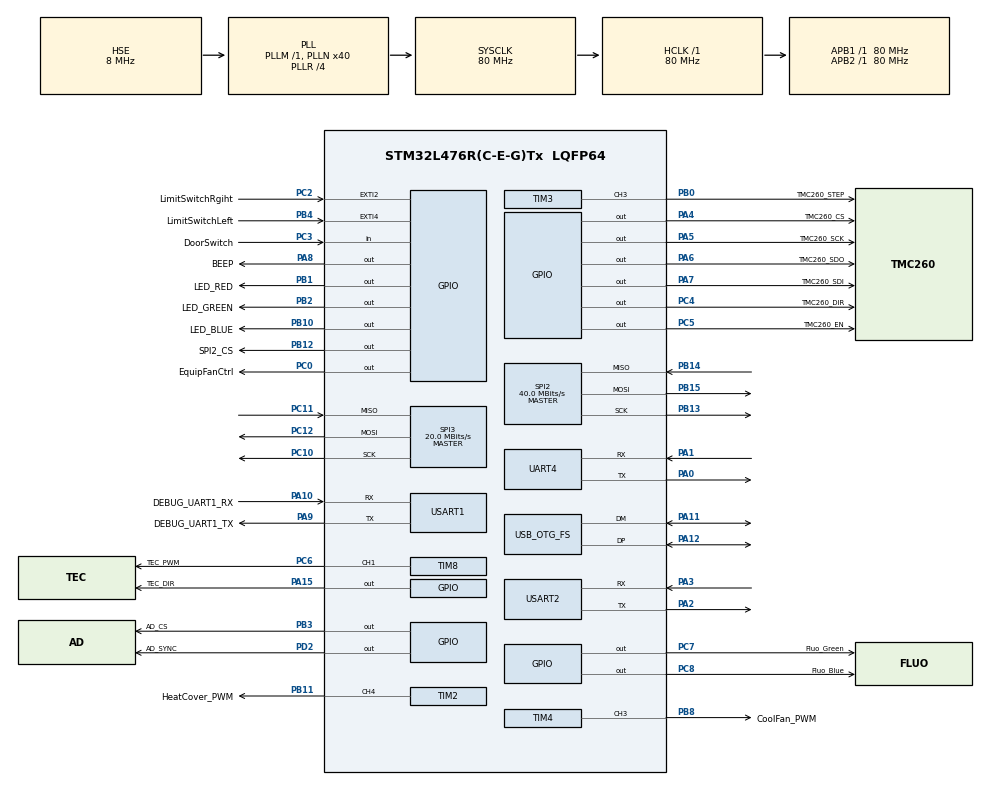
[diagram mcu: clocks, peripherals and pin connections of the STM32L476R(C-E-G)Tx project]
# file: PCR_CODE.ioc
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Dma.Request0=UART4_TX
Dma.Request1=USART2_TX
Dma.UART4_TX.0.Direction=DMA_MEMORY_TO_PERIPH
Dma.UART4_TX.0.Instance=DMA2_Channel3
Dma.UART4_TX.0.MemDataAlignment=DMA_MDATAALIGN_BYTE
Dma.UART4_TX.0.MemInc=DMA_MINC_ENABLE
Dma.UART4_TX.0.Mode=DMA_NORMAL
Dma.UART4_TX.0.PeriphDataAlignment=DMA_PDATAALIGN_BYTE
Dma.UART4_TX.0.PeriphInc=DMA_PINC_DISABLE
Dma.UART4_TX.0.Priority=DMA_PRIORITY_LOW
Dma.USART2_TX.1.Direction=DMA_MEMORY_TO_PERIPH
Dma.USART2_TX.1.Instance=DMA1_Channel7
Dma.USART2_TX.1.MemDataAlignment=DMA_MDATAALIGN_BYTE
Dma.USART2_TX.1.MemInc=DMA_MINC_ENABLE
Dma.USART2_TX.1.Mode=DMA_NORMAL
Dma.USART2_TX.1.PeriphDataAlignment=DMA_PDATAALIGN_BYTE
Dma.USART2_TX.1.PeriphInc=DMA_PINC_DISABLE
Dma.USART2_TX.1.Priority=DMA_PRIORITY_LOW
FATFS._CODE_PAGE=437
FATFS._MAX_SS=4096
FATFS._USE_LFN=3
Mcu.Family=STM32L4
Mcu.Name=STM32L476R(C-E-G)Tx
Mcu.Package=LQFP64
NVIC.DMA1_Channel7_IRQn=true\:0\:0\:false\:false\:true\:false\:true
NVIC.DMA2_Channel3_IRQn=true\:3\:0\:true\:false\:true\:false\:true
NVIC.EXTI2_IRQn=true\:4\:0\:true\:false\:true\:true\:true
NVIC.EXTI4_IRQn=true\:4\:0\:true\:false\:true\:true\:true
NVIC.OTG_FS_IRQn=true\:8\:0\:true\:false\:true\:false\:true
NVIC.PriorityGroup=NVIC_PRIORITYGROUP_4
NVIC.TIM3_IRQn=true\:2\:0\:true\:false\:true\:true\:false
NVIC.TIM6_DAC_IRQn=true\:5\:0\:true\:false\:true\:true\:false
NVIC.TIM7_IRQn=true\:1\:0\:true\:false\:true\:true\:false
NVIC.UART4_IRQn=true\:3\:0\:true\:false\:true\:true\:true
NVIC.USART2_IRQn=true\:0\:0\:false\:false\:true\:true\:true
PA0.Mode=Asynchronous
PA0.Signal=UART4_TX
PA1.Mode=Asynchronous
PA1.Signal=UART4_RX
PA10.GPIO_Label=DEBUG_UART1_RX
PA10.Mode=Asynchronous
PA10.Signal=USART1_RX
PA11.Mode=Host_Only
PA11.Signal=USB_OTG_FS_DM
PA12.Mode=Host_Only
PA12.Signal=USB_OTG_FS_DP
PA13\ (JTMS-SWDIO).Mode=Serial_Wire
PA13\ (JTMS-SWDIO).Signal=SYS_JTMS-SWDIO
PA14\ (JTCK-SWCLK).Mode=Serial_Wire
PA14\ (JTCK-SWCLK).Signal=SYS_JTCK-SWCLK
PA15\ (JTDI).GPIO_Label=TEC_DIR
PA15\ (JTDI).Signal=GPIO_Output
PA2.Mode=Asynchronous
PA2.Signal=USART2_TX
PA3.Mode=Asynchronous
PA3.Signal=USART2_RX
PA4.GPIO_Label=TMC260_CS
PA4.GPIO_PuPd=GPIO_PULLUP
PA4.PinState=GPIO_PIN_SET
PA4.Signal=GPIO_Output
PA5.GPIO_Label=TMC260_SCK
PA5.GPIO_PuPd=GPIO_PULLUP
PA5.GPIO_Speed=GPIO_SPEED_FREQ_HIGH
PA5.Signal=GPIO_Output
PA6.GPIO_Label=TMC260_SDO
PA6.GPIO_PuPd=GPIO_PULLUP
PA6.GPIO_Speed=GPIO_SPEED_FREQ_HIGH
PA6.Signal=GPIO_Output
PA7.GPIO_Label=TMC260_SDI
PA7.GPIO_PuPd=GPIO_PULLUP
PA7.GPIO_Speed=GPIO_SPEED_FREQ_HIGH
PA7.Signal=GPIO_Output
PA8.GPIO_Label=BEEP
PA8.GPIO_PuPd=GPIO_PULLUP
PA8.Signal=GPIO_Output
PA9.GPIO_Label=DEBUG_UART1_TX
PA9.Mode=Asynchronous
PA9.Signal=USART1_TX
PB0.GPIO_Label=TMC260_STEP
PB0.Signal=S_TIM3_CH3
PB1.GPIO_Label=LED_RED
PB1.GPIO_PuPd=GPIO_PULLUP
PB1.GPIO_Speed=GPIO_SPEED_FREQ_LOW
PB1.Signal=GPIO_Output
PB10.GPIO_Label=LED_BLUE
PB10.GPIO_PuPd=GPIO_PULLUP
PB10.Signal=GPIO_Output
PB11.GPIO_Label=HeatCover_PWM
PB11.Signal=S_TIM2_CH4
PB12.GPIO_Label=SPI2_CS
PB12.GPIO_PuPd=GPIO_PULLUP
PB12.GPIO_Speed=GPIO_SPEED_FREQ_LOW
PB12.Signal=GPIO_Output
PB13.Mode=Full_Duplex_Master
PB13.Signal=SPI2_SCK
PB14.Mode=Full_Duplex_Master
PB14.Signal=SPI2_MISO
PB15.Mode=Full_Duplex_Master
PB15.Signal=SPI2_MOSI
PB2.GPIO_Label=LED_GREEN
PB2.GPIO_PuPd=GPIO_PULLUP
PB2.Signal=GPIO_Output
PB3\ (JTDO-TRACESWO).GPIO_Label=AD_CS
PB3\ (JTDO-TRACESWO).GPIO_PuPd=GPIO_PULLUP
PB3\ (JTDO-TRACESWO).Signal=GPIO_Output
PB4\ (NJTRST).GPIO_Label=LimitSwitchLeft
PB4\ (NJTRST).GPIO_ModeDefaultEXTI=GPIO_MODE_IT_FALLING
PB4\ (NJTRST).Signal=GPXTI4
PB8.GPIO_Label=CoolFan_PWM
PB8.Signal=S_TIM4_CH3
PC0.GPIO_Label=EquipFanCtrl
PC0.GPIO_PuPd=GPIO_PULLUP
PC0.Signal=GPIO_Output
PC10.Mode=Full_Duplex_Master
PC10.Signal=SPI3_SCK
PC11.Mode=Full_Duplex_Master
PC11.Signal=SPI3_MISO
PC12.Mode=Full_Duplex_Master
PC12.Signal=SPI3_MOSI
PC2.GPIO_Label=LimitSwitchRgiht
PC2.GPIO_ModeDefaultEXTI=GPIO_MODE_IT_FALLING
PC2.Signal=GPXTI2
PC3.GPIO_Label=DoorSwitch
PC3.Signal=GPIO_Input
PC4.GPIO_Label=TMC260_DIR
PC4.GPIO_PuPd=GPIO_PULLUP
PC4.GPIO_Speed=GPIO_SPEED_FREQ_LOW
PC4.Signal=GPIO_Output
PC5.GPIO_Label=TMC260_EN
PC5.GPIO_PuPd=GPIO_PULLUP
PC5.GPIO_Speed=GPIO_SPEED_FREQ_LOW
PC5.PinState=GPIO_PIN_SET
PC5.Signal=GPIO_Output
PC6.GPIO_Label=TEC_PWM
PC6.Signal=S_TIM8_CH1
PC7.GPIO_Label=Fluo_Green
PC7.GPIO_PuPd=GPIO_PULLUP
PC7.GPIO_Speed=GPIO_SPEED_FREQ_MEDIUM
PC7.Signal=GPIO_Output
PC8.GPIO_Label=Fluo_Blue
PC8.GPIO_PuPd=GPIO_PULLUP
PC8.GPIO_Speed=GPIO_SPEED_FREQ_MEDIUM
PC8.Signal=GPIO_Output
PD2.GPIO_Label=AD_SYNC
PD2.PinState=GPIO_PIN_SET
PD2.Signal=GPIO_Output
PH0-OSC_IN\ (PH0).Mode=HSE-External-Oscillator
PH0-OSC_IN\ (PH0).Signal=RCC_OSC_IN
PH1-OSC_OUT\ (PH1).Mode=HSE-External-Oscillator
PH1-OSC_OUT\ (PH1).Signal=RCC_OSC_OUT
ProjectManager.HeapSize=0xC00
ProjectManager.StackSize=0x2000
ProjectManager.TargetToolchain=MDK-ARM V5
RCC.ADCFreq_Value=48000000
RCC.AHBFreq_Value=80000000
RCC.APB1Freq_Value=80000000
RCC.APB1TimFreq_Value=80000000
RCC.APB2Freq_Value=80000000
RCC.APB2TimFreq_Value=80000000
RCC.CortexFreq_Value=80000000
RCC.HCLKFreq_Value=80000000
RCC.HSE_VALUE=8000000
RCC.HSI_VALUE=16000000
RCC.LSE_VALUE=32768
RCC.MSI_VALUE=4000000
RCC.PLLN=40
RCC.PLLR=RCC_PLLR_DIV4
RCC.PLLSAI1N=12
RCC.PLLSourceVirtual=RCC_PLLSOURCE_HSE
RCC.SYSCLKFreq_VALUE=80000000
RCC.SYSCLKSource=RCC_SYSCLKSOURCE_PLLCLK
RCC.USBFreq_Value=48000000
RCC.VCOOutputFreq_Value=320000000
SH.S_TIM2_CH4.0=TIM2_CH4,PWM Generation4 CH4
SH.S_TIM3_CH3.0=TIM3_CH3,PWM Generation3 CH3
SH.S_TIM4_CH3.0=TIM4_CH3,PWM Generation3 CH3
SH.S_TIM8_CH1.0=TIM8_CH1,PWM Generation1 CH1
SPI2.BaudRatePrescaler=SPI_BAUDRATEPRESCALER_2
SPI2.CalculateBaudRate=40.0 MBits/s
SPI2.DataSize=SPI_DATASIZE_8BIT
SPI2.Direction=SPI_DIRECTION_2LINES
SPI2.Mode=SPI_MODE_MASTER
SPI2.VirtualType=VM_MASTER
SPI3.BaudRatePrescaler=SPI_BAUDRATEPRESCALER_4
SPI3.CLKPhase=SPI_PHASE_2EDGE
SPI3.CLKPolarity=SPI_POLARITY_HIGH
SPI3.CalculateBaudRate=20.0 MBits/s
SPI3.DataSize=SPI_DATASIZE_8BIT
SPI3.Direction=SPI_DIRECTION_2LINES
SPI3.Mode=SPI_MODE_MASTER
SPI3.VirtualType=VM_MASTER
TIM2.AutoReloadPreload=TIM_AUTORELOAD_PRELOAD_ENABLE
TIM2.Channel-PWM\ Generation4\ CH4=TIM_CHANNEL_4
TIM2.Period=800-1
TIM2.Prescaler=100-1
TIM2.Pulse-PWM\ Generation4\ CH4=40
TIM3.AutoReloadPreload=TIM_AUTORELOAD_PRELOAD_ENABLE
TIM3.Channel-PWM\ Generation3\ CH3=TIM_CHANNEL_3
TIM3.OCMode_PWM-PWM\ Generation3\ CH3=TIM_OCMODE_PWM1
TIM3.OCPolarity_3=TIM_OCPOLARITY_LOW
TIM3.Period=80-1
TIM3.Prescaler=1000-1
TIM3.Pulse-PWM\ Generation3\ CH3=40
TIM4.AutoReloadPreload=TIM_AUTORELOAD_PRELOAD_ENABLE
TIM4.Channel-PWM\ Generation3\ CH3=TIM_CHANNEL_3
TIM4.Period=80-1
TIM4.Prescaler=1000-1
TIM4.Pulse-PWM\ Generation3\ CH3=40-1
TIM6.AutoReloadPreload=TIM_AUTORELOAD_PRELOAD_ENABLE
TIM6.Period=80-1
TIM6.Prescaler=1000-1
TIM7.Period=8000-1
TIM7.Prescaler=1000-1
TIM8.AutoReloadPreload=TIM_AUTORELOAD_PRELOAD_ENABLE
TIM8.Channel-PWM\ Generation1\ CH1=TIM_CHANNEL_1
TIM8.Period=400-1
TIM8.Prescaler=10-1
TIM8.Pulse-PWM\ Generation1\ CH1=2
USART1.VirtualMode-Asynchronous=VM_ASYNC
USART2.VirtualMode-Asynchronous=VM_ASYNC
USB_HOST.USBH_HandleTypeDef=hUsbHostFS
USB_HOST.VirtualModeFS=Msc
USB_OTG_FS.VirtualMode=Host_Only
USB_OTG_FS.phy_itface=HCD_PHY_EMBEDDED
VP_FATFS_VS_Generic.Mode=User_defined
VP_FATFS_VS_USB.Mode=USB
VP_TIM3_VS_ClockSourceINT.Mode=Internal
VP_TIM4_VS_ClockSourceINT.Mode=Internal
VP_TIM6_VS_ClockSourceINT.Mode=Enable_Timer
VP_TIM7_VS_ClockSourceINT.Mode=Enable_Timer
VP_TIM8_VS_ClockSourceINT.Mode=Internal
VP_USB_HOST_VS_USB_HOST_MSC_FS.Mode=MSC_FS
board=custom

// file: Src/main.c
/* USER CODE BEGIN Header */
/**
  ******************************************************************************
  * @file           : main.c
  * @brief          : Main program body
  ******************************************************************************
  * @attention
  *
  * <h2><center>&copy; Copyright (c) 2020 STMicroelectronics.
  * All rights reserved.</center></h2>
  *
  * This software component is licensed by ST under Ultimate Liberty license
  * SLA0044, the "License"; You may not use this file except in compliance with
  * the License. You may obtain a copy of the License at:
  *                             www.st.com/SLA0044
  *
  ******************************************************************************
  */
/* USER CODE END Header */

#include "main.h"
#include "dma.h"
#include "fatfs.h"
#include "spi.h"
#include "tim.h"
#include "usart.h"
#include "usb_host.h"
#include "gpio.h"

void SystemClock_Config(void);
void MX_USB_HOST_Process(void);

/* USER CODE BEGIN 0 */
#include "task_manage.h"
#include "sys_info.h"
/* USER CODE END 0 */

int main(void)
{

  /* MCU Configuration--------------------------------------------------------*/

  /* Reset of all peripherals, Initializes the Flash interface and the Systick. */
  HAL_Init();

  /* Configure the system clock */
  SystemClock_Config();

  /* USER CODE BEGIN SysInit */
__set_PRIMASK(1);//关闭总中断
  /* USER CODE END SysInit */

  /* Initialize all configured peripherals */
  MX_GPIO_Init();
  MX_FATFS_Init();
//  MX_USB_HOST_Init();
  MX_DMA_Init();
  MX_SPI2_Init();
  MX_UART4_Init();
  MX_USART1_UART_Init();
  MX_USART2_UART_Init();
  MX_TIM3_Init();
  MX_TIM6_Init();
  MX_SPI3_Init();
  MX_TIM2_Init();
  MX_TIM7_Init();
  MX_TIM8_Init();
  MX_TIM4_Init();
  /* USER CODE BEGIN 2 */
  SYS_PRINTF("APP Startup. Ver:%s", CONFIG_SYSINFO_FW_Version);
LED_GREEN_ON();
CreatMainTask();
  /* USER CODE END 2 */

  /* Infinite loop */
  /* USER CODE BEGIN WHILE */
//  while (1)
//  {
    /* USER CODE END WHILE */
//    MX_USB_HOST_Process();

    /* USER CODE BEGIN 3 */
//  }
  /* USER CODE END 3 */
}

void SystemClock_Config(void)
{
  RCC_OscInitTypeDef RCC_OscInitStruct = {0};
  RCC_ClkInitTypeDef RCC_ClkInitStruct = {0};
  RCC_PeriphCLKInitTypeDef PeriphClkInit = {0};

  /** Initializes the CPU, AHB and APB busses clocks
  */
  RCC_OscInitStruct.OscillatorType = RCC_OSCILLATORTYPE_HSE;
  RCC_OscInitStruct.HSEState = RCC_HSE_ON;
  RCC_OscInitStruct.PLL.PLLState = RCC_PLL_ON;
  RCC_OscInitStruct.PLL.PLLSource = RCC_PLLSOURCE_HSE;
  RCC_OscInitStruct.PLL.PLLM = 1;
  RCC_OscInitStruct.PLL.PLLN = 40;
  RCC_OscInitStruct.PLL.PLLP = RCC_PLLP_DIV7;
  RCC_OscInitStruct.PLL.PLLQ = RCC_PLLQ_DIV2;
  RCC_OscInitStruct.PLL.PLLR = RCC_PLLR_DIV4;
  if (HAL_RCC_OscConfig(&RCC_OscInitStruct) != HAL_OK)
  {
    Error_Handler();
  }
  /** Initializes the CPU, AHB and APB busses clocks
  */
  RCC_ClkInitStruct.ClockType = RCC_CLOCKTYPE_HCLK|RCC_CLOCKTYPE_SYSCLK
                              |RCC_CLOCKTYPE_PCLK1|RCC_CLOCKTYPE_PCLK2;
  RCC_ClkInitStruct.SYSCLKSource = RCC_SYSCLKSOURCE_PLLCLK;
  RCC_ClkInitStruct.AHBCLKDivider = RCC_SYSCLK_DIV1;
  RCC_ClkInitStruct.APB1CLKDivider = RCC_HCLK_DIV1;
  RCC_ClkInitStruct.APB2CLKDivider = RCC_HCLK_DIV1;

  if (HAL_RCC_ClockConfig(&RCC_ClkInitStruct, FLASH_LATENCY_4) != HAL_OK)
  {
    Error_Handler();
  }
  PeriphClkInit.PeriphClockSelection = RCC_PERIPHCLK_USART1|RCC_PERIPHCLK_USART2
                              |RCC_PERIPHCLK_UART4|RCC_PERIPHCLK_USB;
  PeriphClkInit.Usart1ClockSelection = RCC_USART1CLKSOURCE_PCLK2;
  PeriphClkInit.Usart2ClockSelection = RCC_USART2CLKSOURCE_PCLK1;
  PeriphClkInit.Uart4ClockSelection = RCC_UART4CLKSOURCE_PCLK1;
  PeriphClkInit.UsbClockSelection = RCC_USBCLKSOURCE_PLLSAI1;
  PeriphClkInit.PLLSAI1.PLLSAI1Source = RCC_PLLSOURCE_HSE;
  PeriphClkInit.PLLSAI1.PLLSAI1M = 1;
  PeriphClkInit.PLLSAI1.PLLSAI1N = 12;
  PeriphClkInit.PLLSAI1.PLLSAI1P = RCC_PLLP_DIV7;
  PeriphClkInit.PLLSAI1.PLLSAI1Q = RCC_PLLQ_DIV2;
  PeriphClkInit.PLLSAI1.PLLSAI1R = RCC_PLLR_DIV2;
  PeriphClkInit.PLLSAI1.PLLSAI1ClockOut = RCC_PLLSAI1_48M2CLK;
  if (HAL_RCCEx_PeriphCLKConfig(&PeriphClkInit) != HAL_OK)
  {
    Error_Handler();
  }
  /** Configure the main internal regulator output voltage
  */
  if (HAL_PWREx_ControlVoltageScaling(PWR_REGULATOR_VOLTAGE_SCALE1) != HAL_OK)
  {
    Error_Handler();
  }
}

void Error_Handler(void)
{
}

/************************ (C) COPYRIGHT STMicroelectronics *****END OF FILE****/
